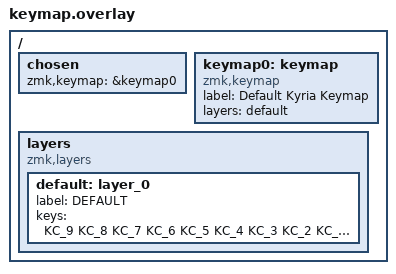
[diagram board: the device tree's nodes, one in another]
#include <dt-bindings/zmk/keys.h>
#include <dt-bindings/zmk/matrix-transform.h>
#include <keymap.h>

/ {
	chosen {
		zmk,keymap = &keymap0;
	};
	
	keymap0: keymap {
		compatible = "zmk,keymap";
		label ="Default Kyria Keymap";
		layers = <&default>;
	};

	layers {
		compatible = "zmk,layers";

		default: layer_0 {
			label = "DEFAULT";
			keys = <KC_9 KC_8 KC_7 KC_6 KC_5 KC_4 KC_3 KC_2 KC_1 KC_0>;
		};
	};
};
